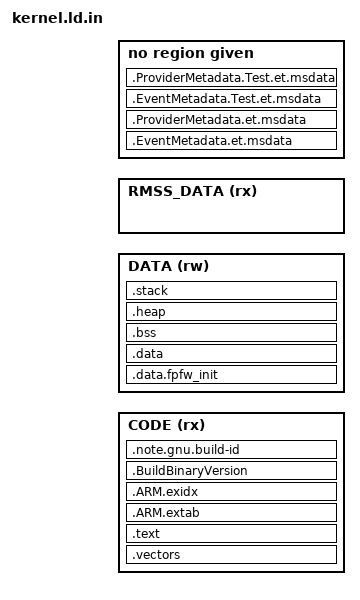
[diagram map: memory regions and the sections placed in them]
/**
 *
 * Copyright (c) Microsoft Corporation. All rights reserved.
 *
*/

/* Before including this .ld file, the following values must be set
   __CODE_START__
   __CODE_SIZE__
   __DATA_START__
   __DATA_SIZE__
   __RMSS_DATA_START__
   __RMSS_DATA_SIZE__
   __DATA_SIZE__
   __STACKSIZE__

   These should be derived from the global memory map for the target controller
*/

/* see NOTE_GNU_BUILD_ID */
_EXPECTED_BUILD_ID_SIZE = 0x24;

ENTRY(reset_handler)

MEMORY
{
  CODE   (rx) : ORIGIN = __CODE_START__, LENGTH = __CODE_SIZE__
  DATA   (rw) : ORIGIN = __DATA_START__, LENGTH = __DATA_SIZE__
  RMSS_DATA   (rx) : ORIGIN = __RMSS_DATA_START__, LENGTH = __RMSS_DATA_SIZE__
}

SECTIONS
{
    .vectors :
    {
        KEEP(*(.vectors .vectors.*))
    } > CODE

    .text :
    {
        *(.text*)

        KEEP(*(.init))
        KEEP(*(.fini))

        /* .ctors */
        *crtbegin.o(.ctors)
        *crtbegin?.o(.ctors)
        *(EXCLUDE_FILE(*crtend?.o *crtend.o) .ctors)
        __ctors_start__ = ALIGN(4);
        *(SORT(.ctors.*))
        *(.ctors)
        __ctors_end__ = ALIGN(4);

        /* .dtors */
         *crtbegin.o(.dtors)
         *crtbegin?.o(.dtors)
         *(EXCLUDE_FILE(*crtend?.o *crtend.o) .dtors)
        __dtors_start__ = ALIGN(4);
         *(SORT(.dtors.*))
         *(.dtors)
        __dtors_end__ = ALIGN(4);

        KEEP(*(.eh_frame*))
    } > CODE

    .ARM.extab :
    {
        *(.ARM.extab* .gnu.linkonce.armextab.*)
    } > CODE

    __exidx_start = .;
    .ARM.exidx :
    {
        *(.ARM.exidx* .gnu.linkonce.armexidx.*)
    } > CODE
    __exidx_end = .;

    .BuildBinaryVersion :
    {
        *(.BuildBinaryVersion)
    } > CODE

    .note.gnu.build-id (READONLY): ALIGN(4)
    {
        PROVIDE(g_note_gnu_build_id = .);
        _build_id_msdata_start = ABSOLUTE(.);
        *(.note.gnu.build-id)
        . = ALIGN (4);
        _build_id_msdata_end = ABSOLUTE(.);
    } > CODE

    ASSERT((_build_id_msdata_end - _build_id_msdata_start) == _EXPECTED_BUILD_ID_SIZE, "Error: build id size not expected!")

    .data.fpfw_init (READONLY): ALIGN(4)
    {
        _data_fpfw_init_start = ABSOLUTE(.);
        KEEP(*(.data.fpfw_init))
        . = ALIGN (4);
        _data_fpfw_init_end = ABSOLUTE(.);
    } > DATA

    .data :
    {
        /* TODO: These shouldn't be needed by the entry point, since bootloader already copies DTCM to DTCM RAM */
        /* ADO: 2349367 */
        __data_load_start__ = LOADADDR(.data);
        __data_start__ = ABSOLUTE(.);

        *(.data*)

        . = ALIGN(4);
        /* preinit data */
        PROVIDE_HIDDEN (__preinit_array_start = .);
        KEEP(*(.preinit_array))
        PROVIDE_HIDDEN (__preinit_array_end = .);

        . = ALIGN(4);
        /* init data */
        PROVIDE_HIDDEN (__init_array_start = .);
        KEEP(*(SORT(.init_array.*)))
        KEEP(*(.init_array))
        PROVIDE_HIDDEN (__init_array_end = .);

        . = ALIGN(4);
        /* finit data */
        PROVIDE_HIDDEN (__fini_array_start = .);
        KEEP(*(SORT(.fini_array.*)))
        KEEP(*(.fini_array))
        PROVIDE_HIDDEN (__fini_array_end = .);

        KEEP(*(.jcr*))
        . = ALIGN(4);

        /**
        * All code accessible sections needed for Event Trace. Used for filtering events.
        * Will be 0 sized if Event Trace is not used. Grows as providers grow.
        * Placed in DTCM.
        */
        _data_etproviderfilter_start = ABSOLUTE(.);
        KEEP(*(.ProviderFilters.et.msdata))
        . = ALIGN (4);
        _data_etproviderfilter_end = ABSOLUTE(.);

        /* All data end */
        __data_end__ = .;
    } > DATA

    .bss :
    {
        . = ALIGN(4);
        __bss_start__ = .;
        *(.bss*)
        *(COMMON)
        . = ALIGN(4);
        __bss_end__ = .;
    } > DATA

    /* Use the remaining data allotment for the .heap section */
    /* The C runtime expects .heap to follow .bss */
    .heap :
    {
        __heap_start__ = ALIGN(4);
        /* "end" indicates the end of .bss and beginning of the .heap */
        PROVIDE (end = .);
        PROVIDE (_end = .);
        FILL(0x00);
        *(.heap)
        /* Move the pointer to the desired beginning of the stack minus one byte
           then use the BYTE(0x00) command to insert a byte at the end of this section.
           This ensures that the section will contain data and will be appropriately filled
           in the output */
        . = ORIGIN(DATA) + LENGTH(DATA) - 1 - __STACKSIZE__;
        BYTE(0x00);
        __heap_end__ = ALIGN(4);
        PROVIDE(heap_end = .);
    } > DATA

    .stack ALIGN(4):
    {
        __stack_start__ = ALIGN(4);
        FILL(0x00)
        *(.stack)
        . = ALIGN(. + __STACKSIZE__, 4) - 1;
        BYTE(0)
        __stack_end__ = ALIGN(4);
        PROVIDE (__stack = .);
    } > DATA

    __HEAPSIZE__ = __heap_end__ - __heap_start__;

    __RAM_segment_used_end__ = .;

    @RODATA_SECTION@ :
    {
        __placed_rodata_start__ = ALIGN(4);
        *(.rodata*)
        __placed_code_start__ = ALIGN(4);
        KEEP(*(.placed.code))
        __placed_code_end__ = ALIGN(4);
    } > @RODATA_REGION@

    .EventMetadata.et.msdata (READONLY): ALIGN(4)
    {
        _EventMetadata_et_msdata_start = ABSOLUTE(.);
        KEEP(*(.EventMetadata.et.msdata))
        . = ALIGN (4);
        _EventMetadata_et_msdata_end = ABSOLUTE(.);
    } > @RODATA_REGION@

    .ProviderMetadata.et.msdata (READONLY): ALIGN(4)
    {
        _ProviderMetadata_et_msdata_start = ABSOLUTE(.);
        KEEP(*(.ProviderMetadata.et.msdata))
        . = ALIGN (4);
        _ProviderMetadata_et_msdata_end = ABSOLUTE(.);
    } > @RODATA_REGION@

    .EventMetadata.Test.et.msdata (READONLY): ALIGN(4)
    {
        _EventMetadata_Test_et_msdata_start = ABSOLUTE(.);
        KEEP(*(.EventMetadata.Test.et.msdata))
        . = ALIGN (4);
        _EventMetadata_Test_et_msdata_end = ABSOLUTE(.);
    } > @RODATA_REGION@

    .ProviderMetadata.Test.et.msdata (READONLY): ALIGN(4)
    {
        _ProviderMetadata_Test_et_msdata_start = ABSOLUTE(.);
        KEEP(*(.ProviderMetadata.Test.et.msdata))
        . = ALIGN (4);
        _ProviderMetadata_Test_et_msdata_end = ABSOLUTE(.);
    } > @RODATA_REGION@

    /* Create linker variables for the RODATA region, used for displaying sizes */
    /* Calculate the sizes */
    ro_data_size = __placed_code_start__ - __placed_rodata_start__;
    ro_code_size = __placed_code_end__ - __placed_code_start__;
    ro_metadata_size = SIZEOF(.EventMetadata.et.msdata) + SIZEOF(.ProviderMetadata.et.msdata) + SIZEOF(.EventMetadata.Test.et.msdata) + SIZEOF(.ProviderMetadata.Test.et.msdata);

    /* Calculate how much was used and how much is allocated to ro use cases */
    ro_total_used_size = SIZEOF(@RODATA_SECTION@) + ro_metadata_size;
    ro_total_size = LENGTH(@RODATA_REGION@) - (__placed_rodata_start__ - ORIGIN(@RODATA_REGION@));
}
